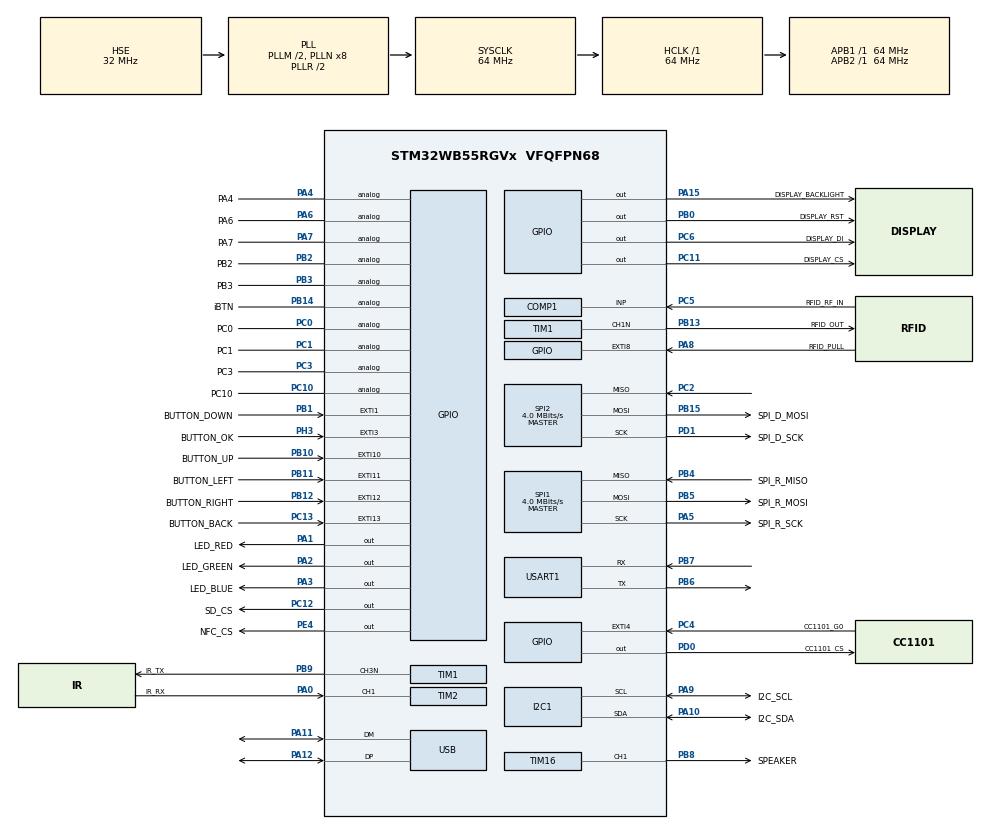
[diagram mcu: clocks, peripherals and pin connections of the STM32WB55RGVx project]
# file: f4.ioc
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PA11.GPIO_Speed=GPIO_SPEED_FREQ_VERY_HIGH
SPI1.VirtualType=VM_MASTER
PB10.GPIO_PuPd=GPIO_PULLUP
RF1.Signal=RF_RF1
SPI2.VirtualType=VM_MASTER
VP_ADC1_TempSens_Input.Mode=IN-TempSens
PC12.Signal=GPIO_Output
PB14.GPIO_Label=iBTN
PC6.GPIO_Label=DISPLAY_DI
VP_RTC_VS_RTC_Activate.Mode=RTC_Enabled
PA6.GPIO_Label=PA6
COMP1.Hysteresis=COMP_HYSTERESIS_HIGH
PA3.GPIO_Speed=GPIO_SPEED_FREQ_LOW
PB13.Signal=TIM1_CH1N
PC15-OSC32_OUT.GPIO_Label=QUARTZ_32MHZ_OUT
RCC.SYSCLKSource=RCC_SYSCLKSOURCE_PLLCLK
FREERTOS.configENABLE_FPU=1
NVIC.EXTI1_IRQn=true\:5\:0\:true\:false\:true\:false\:true\:true
NVIC.ADC1_IRQn=true\:5\:0\:true\:false\:true\:false\:true\:true
SPI1.Direction=SPI_DIRECTION_2LINES
RCC.APB2TimFreq_Value=64000000
COMP1.Mode=COMP_POWERMODE_MEDIUMSPEED
PB6.Signal=USART1_TX
PB6.Mode=Asynchronous
NVIC.TAMP_STAMP_LSECSS_IRQn=true\:5\:0\:false\:false\:true\:true\:true\:true
SPI1.CalculateBaudRate=4.0 MBits/s
PC3.Signal=GPIO_Analog
PD0.Signal=GPIO_Output
RCC.PREFETCH_ENABLE=1
NVIC.EXTI15_10_IRQn=true\:5\:0\:true\:false\:true\:false\:true\:true
PB2.Signal=GPIO_Analog
RCC.RTCClockSelection=RCC_RTCCLKSOURCE_LSE
PD1.GPIO_Label=SPI_D_SCK
PB12.GPIO_Label=BUTTON_RIGHT
LPTIM1.ClockPrescaler=LPTIM_PRESCALER_DIV32
VP_ADC1_Vref_Input.Mode=IN-Vrefint
PC4.GPIO_Label=CC1101_G0
FREERTOS.HEAP_NUMBER=4
RCC.LSE_Drive_Capability=RCC_LSEDRIVE_MEDIUMLOW
PB1.GPIO_Label=BUTTON_DOWN
NVIC.TIM2_IRQn=true\:5\:0\:true\:false\:true\:false\:true\:true
SPI1.DataSize=SPI_DATASIZE_8BIT
PE4.GPIO_Label=NFC_CS
SPI2.CalculateBaudRate=4.0 MBits/s
PA8.Signal=GPXTI8
VP_TIM1_VS_ClockSourceINT.Mode=Internal
ADC1.SamplingTime-0\#ChannelRegularConversion=ADC_SAMPLETIME_2CYCLES_5
TIM16.Pulse=145
PA0.Signal=S_TIM2_CH1
PH3-BOOT0.Signal=GPXTI3
NVIC.HSEM_IRQn=true\:5\:0\:true\:false\:true\:false\:false\:true
PB9.Signal=TIM1_CH3N
Mcu.Package=VFQFPN68
TIM2.Prescaler=64-1
PB1.Signal=GPXTI1
NVIC.TimeBase=TIM1_TRG_COM_TIM17_IRQn
SPI2.Mode=SPI_MODE_MASTER
PA2.GPIO_ModeDefaultOutputPP=GPIO_MODE_OUTPUT_OD
VP_PKA_VS_PKA.Mode=PKA_Activate
NVIC.TimeBaseIP=TIM17
PA10.Signal=I2C1_SDA
VP_RTC_VS_RTC_Calendar.Mode=RTC_Calendar
PA1.PinState=GPIO_PIN_SET
NVIC.USB_LP_IRQn=true\:5\:0\:true\:false\:true\:false\:false\:true
VP_HSEM_VS_HSEM.Mode=HSEM_Activate
RCC.APB1TimFreq_Value=64000000
FREERTOS.configGENERATE_RUN_TIME_STATS=1
PB13.Mode=Output Compare1 CH1N
TIM16.Prescaler=500 - 1
I2C1.CustomTiming=Disabled
RCC.SMPSDivider=4
PA4.GPIO_Label=PA4
NVIC.RCC_IRQn=true\:5\:0\:false\:false\:true\:true\:true\:false
RCC.HSI48_VALUE=48000000
PA5.Mode=Full_Duplex_Master
PC4.GPIO_ModeDefaultEXTI=GPIO_MODE_IT_RISING_FALLING
PA3.GPIO_ModeDefaultOutputPP=GPIO_MODE_OUTPUT_OD
FREERTOS.Tasks01=app_main,24,1024,app,As weak,NULL,Dynamic,NULL,NULL
ADC1.Rank-0\#ChannelRegularConversion=1
VP_SYS_VS_tim17.Mode=TIM17
ADC1.OffsetNumber-0\#ChannelRegularConversion=ADC_OFFSET_NONE
PA9.GPIO_Label=I2C_SCL
PC13.Signal=GPXTI13
FREERTOS.configCHECK_FOR_STACK_OVERFLOW=1
PC2.Signal=SPI2_MISO
PC6.Signal=GPIO_Output
PB11.GPIO_Label=BUTTON_LEFT
PD1.Signal=SPI2_SCK
SH.S_TIM16_CH1.0=TIM16_CH1,PWM Generation1 CH1
VP_TIM16_VS_ClockSourceINT.Mode=Enable_Timer
SPI1.CLKPhase=SPI_PHASE_2EDGE
PC0.Signal=GPIO_Analog
PC14-OSC32_IN.Signal=RCC_OSC32_IN
PD0.GPIO_Speed=GPIO_SPEED_FREQ_VERY_HIGH
PB8.GPIO_Label=SPEAKER
PA8.GPIO_Label=RFID_PULL
PC12.PinState=GPIO_PIN_SET
USB_DEVICE.PRODUCT_STRING_CDC_FS=Flipper Control Virtual ComPort
PA9.Signal=I2C1_SCL
I2C1.Timing=0x10707DBC
OSC_IN.Signal=RCC_OSC_IN
PB10.Signal=GPXTI10
PB14.Signal=GPIO_Analog
PA5.Signal=SPI1_SCK
PD1.Mode=Full_Duplex_Master
NVIC.LPTIM1_IRQn=true\:5\:0\:true\:false\:true\:false\:true\:true
RCC.RNGCLockSelection=RCC_RNGCLKSOURCE_CLK48
PB4.GPIO_Label=SPI_R_MISO
PB15.GPIO_Label=SPI_D_MOSI
SPI1.Mode=SPI_MODE_MASTER
NVIC.COMP_IRQn=true\:5\:0\:true\:false\:true\:false\:false\:true
PA1.GPIO_Label=LED_RED
PA13.Mode=Serial_Wire
PB10.GPIO_ModeDefaultEXTI=GPIO_MODE_IT_RISING_FALLING
PA4.Signal=GPIO_Analog
PB5.Signal=SPI1_MOSI
ADC1.master=1
PA5.GPIO_Label=SPI_R_SCK
OSC_IN.Mode=HSE-External-Oscillator
PC12.GPIO_Label=SD_CS
PA11.Signal=USB_DM
ProjectManager.HeapSize=0x400
NVIC.PriorityGroup=NVIC_PRIORITYGROUP_4
USB_DEVICE.APP_RX_DATA_SIZE=512
TIM2.AutoReloadPreload=TIM_AUTORELOAD_PRELOAD_ENABLE
PC3.GPIO_Label=PC3
PA3.PinState=GPIO_PIN_SET
PE4.PinState=GPIO_PIN_SET
SPI2.DataSize=SPI_DATASIZE_8BIT
VP_AES1_VS_AES.Mode=AES_Activate
PB12.GPIO_PuPd=GPIO_PULLUP
PB0.Signal=GPIO_Output
PC1.Signal=GPIO_Analog
Mcu.Family=STM32WB
OSC_OUT.GPIO_Label=QUARTZ_32KHZ_OUT
USB_DEVICE.CLASS_NAME_FS=CDC
RCC.CortexFreq_Value=64000000
TIM2.Channel-Input_Capture1_from_TI1=TIM_CHANNEL_1
ADC1.ContinuousConvMode=DISABLE
PC10.Signal=GPIO_Analog
PA0.GPIO_Label=IR_RX
PA2.GPIO_Speed=GPIO_SPEED_FREQ_LOW
PH3-BOOT0.GPIO_Label=BUTTON_OK
NVIC.EXTI3_IRQn=true\:5\:0\:true\:false\:true\:false\:true\:true
PD0.GPIO_Label=CC1101_CS
PC0.GPIO_Label=PC0
PA11.Mode=Device
PB0.GPIO_Label=DISPLAY_RST
FREERTOS.configTICK_RATE_HZ=1000
PB11.GPIO_PuPd=GPIO_PULLUP
PC13.GPIO_Label=BUTTON_BACK
PB13.GPIO_Label=RFID_OUT
PB11.Signal=GPXTI11
PB15.Signal=SPI2_MOSI
ProjectManager.StackSize=0x1000
VP_FREERTOS_VS_CMSIS_V2.Mode=CMSIS_V2
USB_DEVICE.MANUFACTURER_STRING=Flipper
PA15.GPIO_Label=DISPLAY_BACKLIGHT
PA12.Signal=USB_DP
TIM2.ICPolarity_CH1=TIM_INPUTCHANNELPOLARITY_FALLING
PB1.GPIO_PuPd=GPIO_PULLUP
RCC.HCLKFreq_Value=64000000
PB1.GPIO_ModeDefaultEXTI=GPIO_MODE_IT_RISING_FALLING
OSC_OUT.Mode=HSE-External-Oscillator
OSC_OUT.Signal=RCC_OSC_OUT
RCC.AHBFreq_Value=64000000
SPI2.BaudRatePrescaler=SPI_BAUDRATEPRESCALER_16
ADC1.Channel-0\#ChannelRegularConversion=ADC_CHANNEL_14
RCC.HSE_VALUE=32000000
FREERTOS.configUSE_TIMERS=1
FREERTOS.configENABLE_BACKWARD_COMPATIBILITY=0
NVIC.TIM1_TRG_COM_TIM17_IRQn=true\:0\:0\:false\:false\:true\:false\:false\:true
PA2.PinState=GPIO_PIN_SET
PB4.Mode=Full_Duplex_Master
RCC.LSE_Timout=1000
PC14-OSC32_IN.Mode=LSE-External-Oscillator
PD0.PinState=GPIO_PIN_SET
PA14.Mode=Serial_Wire
PE4.GPIO_Speed=GPIO_SPEED_FREQ_VERY_HIGH
PC11.GPIO_Label=DISPLAY_CS
PB5.Mode=Full_Duplex_Master
PA10.GPIO_Label=I2C_SDA
PC13.GPIO_PuPd=GPIO_PULLUP
PB7.Signal=USART1_RX
FREERTOS.INCLUDE_vTaskCleanUpResources=1
PE4.Signal=GPIO_Output
FREERTOS.configTOTAL_HEAP_SIZE=40960
RCC.APB3Freq_Value=16000000
PA6.Signal=GPIO_Analog
TIM2.Channel-Input_Capture2_from_TI1=TIM_CHANNEL_2
RCC.EnbaleCSS=true
PA2.GPIO_Label=LED_GREEN
PB11.GPIO_ModeDefaultEXTI=GPIO_MODE_IT_RISING_FALLING
VP_LPTIM1_VS_LPTIM_counterModeInternalClock.Mode=Counts__internal_clock_event_00
PA15.Signal=GPIO_Output
RCC.MSIOscState=DISABLED
SPI2.CLKPhase=SPI_PHASE_1EDGE
PA10.GPIO_Speed=GPIO_SPEED_FREQ_VERY_HIGH
PB5.GPIO_Label=SPI_R_MOSI
VP_AES2_VS_AES.Mode=AES_Activate
PC14-OSC32_IN.GPIO_Label=QUARTZ_32MHZ_IN
SPI2.Direction=SPI_DIRECTION_2LINES
PC5.Signal=SharedAnalog_PC5
SPI1.BaudRatePrescaler=SPI_BAUDRATEPRESCALER_16
OSC_IN.GPIO_Label=QUARTZ_32KHZ_IN
PA12.GPIO_Speed=GPIO_SPEED_FREQ_VERY_HIGH
COMP1.TriggerMode=COMP_TRIGGERMODE_IT_RISING_FALLING
PB4.Signal=SPI1_MISO
RCC.PLLSAI1N=6
PA3.Signal=GPIO_Output
PB3.GPIO_Label=PB3
RCC.PLLSourceVirtual=RCC_PLLSOURCE_HSE
PC15-OSC32_OUT.Mode=LSE-External-Oscillator
SH.S_TIM2_CH1.1=TIM2_CH1,Input_Capture2_from_TI1
SH.S_TIM2_CH1.0=TIM2_CH1,Input_Capture1_from_TI1
PB9.GPIO_Label=IR_TX
PC10.GPIO_Label=PC10
PA10.Mode=I2C
USB_DEVICE.VirtualModeFS=Cdc_FS
PC4.GPIO_PuPd=GPIO_PULLDOWN
PC11.Signal=GPIO_Output
FREERTOS.configUSE_TICKLESS_IDLE=2
PC4.Signal=GPXTI4
PC2.Mode=Full_Duplex_Master
VP_RNG_VS_RNG.Mode=RNG_Activate
TIM16.Channel=TIM_CHANNEL_1
RCC.AHB2CLKDivider=RCC_SYSCLK_DIV2
USART1.VirtualMode-Asynchronous=VM_ASYNC
PA13.Signal=SYS_JTMS-SWDIO
FREERTOS.configUSE_IDLE_HOOK=1
VP_COMP1_VS_VREFINT14.Mode=VREFINT_14
PA9.Mode=I2C
TIM1.Channel-Output\ Compare1\ CH1N=TIM_CHANNEL_1
FREERTOS.configRECORD_STACK_HIGH_ADDRESS=1
ProjectManager.TargetToolchain=Makefile
PB10.GPIO_Label=BUTTON_UP
VP_USB_DEVICE_VS_USB_DEVICE_CDC_FS.Mode=CDC_FS
PB9.Mode=PWM Generation3 CH3N
RCC.LPTIM1CLockSelection=RCC_LPTIM1CLKSOURCE_LSE
ADC1.EnableAnalogWatchDog1=false
RCC.USBFreq_Value=48000000
TIM1.Channel-PWM\ Generation3\ CH3N=TIM_CHANNEL_3
PC15-OSC32_OUT.Signal=RCC_OSC32_OUT
PA1.Signal=GPIO_Output
RCC.SMPSCLockSelectionVirtual=RCC_SMPSCLKSOURCE_HSE
board=custom
RCC.VCOOutputFreq_Value=128000000
PB15.Mode=Full_Duplex_Master
TIM16.Period=291
RCC.APB2Freq_Value=64000000
PC11.PinState=GPIO_PIN_SET
VP_TIM2_VS_ClockSourceINT.Mode=Internal
PA1.GPIO_Speed=GPIO_SPEED_FREQ_LOW
SH.SharedAnalog_PC5.0=COMP1_INP,INP
RCC.ADCFreq_Value=48000000
PC1.GPIO_Label=PC1
SH.SharedAnalog_PC5.1=ADC1_IN14,IN14-Single-Ended
PH3-BOOT0.GPIO_ModeDefaultEXTI=GPIO_MODE_IT_RISING_FALLING
Mcu.Name=STM32WB55RGVx
RCC.EnableCSSLSE=true
PA2.Signal=GPIO_Output
PB3.Signal=GPIO_Analog
RCC.SYSCLKFreq_VALUE=64000000
PA7.GPIO_Label=PA7
PA12.Mode=Device
PC13.GPIO_ModeDefaultEXTI=GPIO_MODE_IT_RISING_FALLING
PC5.GPIO_Label=RFID_RF_IN
RF1.Mode=RF1_Activate
PB7.Mode=Asynchronous
NVIC.EXTI9_5_IRQn=true\:5\:0\:true\:false\:true\:false\:true\:true
USB_DEVICE.APP_TX_DATA_SIZE=512
PA14.Signal=SYS_JTCK-SWCLK
PB2.GPIO_Label=PB2
PB12.GPIO_ModeDefaultEXTI=GPIO_MODE_IT_RISING_FALLING
RCC.HSI_VALUE=16000000
ADC1.NbrOfConversionFlag=1
RCC.PLLM=RCC_PLLM_DIV2
PA15.GPIO_PuPd=GPIO_PULLDOWN
PB8.Signal=S_TIM16_CH1
PA9.GPIO_Speed=GPIO_SPEED_FREQ_VERY_HIGH
RCC.APB1Freq_Value=64000000
RCC.RFWKPClockSelection=RCC_RFWKPCLKSOURCE_LSE
PC12.GPIO_Speed=GPIO_SPEED_FREQ_VERY_HIGH
VP_CRC_VS_CRC.Mode=CRC_Activate
USB_DEVICE.VirtualMode=Cdc
PB12.Signal=GPXTI12
PA3.GPIO_Label=LED_BLUE
PA7.Signal=GPIO_Analog
PA1.GPIO_ModeDefaultOutputPP=GPIO_MODE_OUTPUT_OD

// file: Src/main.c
/* USER CODE BEGIN Header */
/**
  ******************************************************************************
  * @file           : main.c
  * @brief          : Main program body
  ******************************************************************************
  * @attention
  *
  * <h2><center>&copy; Copyright (c) 2020 STMicroelectronics.
  * All rights reserved.</center></h2>
  *
  * This software component is licensed by ST under Ultimate Liberty license
  * SLA0044, the "License"; You may not use this file except in compliance with
  * the License. You may obtain a copy of the License at:
  *                             www.st.com/SLA0044
  *
  ******************************************************************************
  */
/* USER CODE END Header */
#include "main.h"
#include "cmsis_os.h"
#include "adc.h"
#include "aes.h"
#include "comp.h"
#include "crc.h"
#include "i2c.h"
#include "pka.h"
#include "rf.h"
#include "rng.h"
#include "rtc.h"
#include "spi.h"
#include "tim.h"
#include "usart.h"
#include "usb_device.h"
#include "gpio.h"

/* USER CODE BEGIN Includes */
#include "fatfs/fatfs.h"
#include "api-hal.h"
/* USER CODE END Includes */

void SystemClock_Config(void);
void MX_FREERTOS_Init(void);

int main(void)
{

  /* MCU Configuration--------------------------------------------------------*/

  /* Reset of all peripherals, Initializes the Flash interface and the Systick. */
  HAL_Init();

  /* Configure the system clock */
  SystemClock_Config();

  /* Initialize all configured peripherals */
  MX_GPIO_Init();
  MX_ADC1_Init();
  MX_I2C1_Init();
  MX_RTC_Init();
  MX_SPI1_Init();
  MX_SPI2_Init();
  MX_USART1_UART_Init();
  MX_USB_Device_Init();
  MX_TIM1_Init();
  MX_TIM2_Init();
  MX_TIM16_Init();
  MX_COMP1_Init();
  MX_RF_Init();
  MX_PKA_Init();
  MX_RNG_Init();
  MX_AES1_Init();
  MX_AES2_Init();
  MX_CRC_Init();
  /* USER CODE BEGIN 2 */
  MX_FATFS_Init();
  delay_us_init_DWT();
  api_hal_vcp_init();
  api_hal_spi_init();
  // Errata 2.2.9, Flash OPTVERR flag is always set after system reset
  __HAL_FLASH_CLEAR_FLAG(FLASH_FLAG_ALL_ERRORS);
  /* USER CODE END 2 */

  /* Init scheduler */
  osKernelInitialize();  /* Call init function for freertos objects (in freertos.c) */
  MX_FREERTOS_Init();
  /* Start scheduler */
  osKernelStart();

  /* We should never get here as control is now taken by the scheduler */
  /* Infinite loop */
  while (1)
  {

  }
}

void SystemClock_Config(void)
{
  RCC_OscInitTypeDef RCC_OscInitStruct = {0};
  RCC_ClkInitTypeDef RCC_ClkInitStruct = {0};
  RCC_PeriphCLKInitTypeDef PeriphClkInitStruct = {0};

  /** Configure LSE Drive Capability
  */
  HAL_PWR_EnableBkUpAccess();
  __HAL_RCC_LSEDRIVE_CONFIG(RCC_LSEDRIVE_MEDIUMLOW);
  /** Configure the main internal regulator output voltage
  */
  __HAL_PWR_VOLTAGESCALING_CONFIG(PWR_REGULATOR_VOLTAGE_SCALE1);
  /** Initializes the RCC Oscillators according to the specified parameters
  * in the RCC_OscInitTypeDef structure.
  */
  RCC_OscInitStruct.OscillatorType = RCC_OSCILLATORTYPE_HSI|RCC_OSCILLATORTYPE_HSE
                              |RCC_OSCILLATORTYPE_LSE;
  RCC_OscInitStruct.HSEState = RCC_HSE_ON;
  RCC_OscInitStruct.LSEState = RCC_LSE_ON;
  RCC_OscInitStruct.HSIState = RCC_HSI_ON;
  RCC_OscInitStruct.HSICalibrationValue = RCC_HSICALIBRATION_DEFAULT;
  RCC_OscInitStruct.PLL.PLLState = RCC_PLL_ON;
  RCC_OscInitStruct.PLL.PLLSource = RCC_PLLSOURCE_HSE;
  RCC_OscInitStruct.PLL.PLLM = RCC_PLLM_DIV2;
  RCC_OscInitStruct.PLL.PLLN = 8;
  RCC_OscInitStruct.PLL.PLLP = RCC_PLLP_DIV2;
  RCC_OscInitStruct.PLL.PLLR = RCC_PLLR_DIV2;
  RCC_OscInitStruct.PLL.PLLQ = RCC_PLLQ_DIV2;
  if (HAL_RCC_OscConfig(&RCC_OscInitStruct) != HAL_OK)
  {
    Error_Handler();
  }
  /** Configure the SYSCLKSource, HCLK, PCLK1 and PCLK2 clocks dividers
  */
  RCC_ClkInitStruct.ClockType = RCC_CLOCKTYPE_HCLK4|RCC_CLOCKTYPE_HCLK2
                              |RCC_CLOCKTYPE_HCLK|RCC_CLOCKTYPE_SYSCLK
                              |RCC_CLOCKTYPE_PCLK1|RCC_CLOCKTYPE_PCLK2;
  RCC_ClkInitStruct.SYSCLKSource = RCC_SYSCLKSOURCE_PLLCLK;
  RCC_ClkInitStruct.AHBCLKDivider = RCC_SYSCLK_DIV1;
  RCC_ClkInitStruct.APB1CLKDivider = RCC_HCLK_DIV1;
  RCC_ClkInitStruct.APB2CLKDivider = RCC_HCLK_DIV1;
  RCC_ClkInitStruct.AHBCLK2Divider = RCC_SYSCLK_DIV2;
  RCC_ClkInitStruct.AHBCLK4Divider = RCC_SYSCLK_DIV1;

  if (HAL_RCC_ClockConfig(&RCC_ClkInitStruct, FLASH_LATENCY_3) != HAL_OK)
  {
    Error_Handler();
  }
  /** Initializes the peripherals clocks
  */
  PeriphClkInitStruct.PeriphClockSelection = RCC_PERIPHCLK_SMPS|RCC_PERIPHCLK_RFWAKEUP
                              |RCC_PERIPHCLK_RTC|RCC_PERIPHCLK_USART1
                              |RCC_PERIPHCLK_I2C1|RCC_PERIPHCLK_CLK48SEL
                              |RCC_PERIPHCLK_USB|RCC_PERIPHCLK_RNG
                              |RCC_PERIPHCLK_ADC;
  PeriphClkInitStruct.PLLSAI1.PLLN = 6;
  PeriphClkInitStruct.PLLSAI1.PLLP = RCC_PLLP_DIV2;
  PeriphClkInitStruct.PLLSAI1.PLLQ = RCC_PLLQ_DIV2;
  PeriphClkInitStruct.PLLSAI1.PLLR = RCC_PLLR_DIV2;
  PeriphClkInitStruct.PLLSAI1.PLLSAI1ClockOut = RCC_PLLSAI1_USBCLK|RCC_PLLSAI1_ADCCLK;
  PeriphClkInitStruct.Usart1ClockSelection = RCC_USART1CLKSOURCE_PCLK2;
  PeriphClkInitStruct.I2c1ClockSelection = RCC_I2C1CLKSOURCE_PCLK1;
  PeriphClkInitStruct.UsbClockSelection = RCC_USBCLKSOURCE_PLLSAI1;
  PeriphClkInitStruct.RngClockSelection = RCC_RNGCLKSOURCE_CLK48;
  PeriphClkInitStruct.AdcClockSelection = RCC_ADCCLKSOURCE_PLLSAI1;
  PeriphClkInitStruct.RTCClockSelection = RCC_RTCCLKSOURCE_LSE;
  PeriphClkInitStruct.RFWakeUpClockSelection = RCC_RFWKPCLKSOURCE_LSE;
  PeriphClkInitStruct.SmpsClockSelection = RCC_SMPSCLKSOURCE_HSE;
  PeriphClkInitStruct.SmpsDivSelection = RCC_SMPSCLKDIV_RANGE1;
  if (HAL_RCCEx_PeriphCLKConfig(&PeriphClkInitStruct) != HAL_OK)
  {
    Error_Handler();
  }
  /** Enables the Clock Security System
  */
  HAL_RCC_EnableCSS();
  /** Enables the Clock Security System
  */
  HAL_RCCEx_EnableLSECSS();
}

void Error_Handler(void)
{
  /* USER CODE BEGIN Error_Handler_Debug */
  /* User can add his own implementation to report the HAL error return state */
  asm("bkpt 1");
  /* USER CODE END Error_Handler_Debug */
}

/************************ (C) COPYRIGHT STMicroelectronics *****END OF FILE****/

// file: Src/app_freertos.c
#include <cmsis_os2.h>
#include <FreeRTOS.h>
#include <task.h>
#include <main.h>

osThreadId_t systemdHandle;
const osThreadAttr_t systemd_attributes = {
    .name = "systemd",
    .priority = (osPriority_t) osPriorityNormal,
    .stack_size = 1024
};

void systemd(void *argument);

void MX_FREERTOS_Init(void); /* (MISRA C 2004 rule 8.1) */

/* Hook prototypes */
void configureTimerForRunTimeStats(void);
unsigned long getRunTimeCounterValue(void);
void vApplicationIdleHook(void);
void vApplicationStackOverflowHook(TaskHandle_t xTask, signed char *pcTaskName);

__weak void configureTimerForRunTimeStats(void) {
}

__weak unsigned long getRunTimeCounterValue(void) {
    return 0;
}

__weak void vApplicationIdleHook( void ) {
    /* vApplicationIdleHook() will only be called if configUSE_IDLE_HOOK is set
    to 1 in FreeRTOSConfig.h. It will be called on each iteration of the idle
    task. It is essential that code added to this hook function never attempts
    to block in any way (for example, call xQueueReceive() with a block time
    specified, or call vTaskDelay()). If the application makes use of the
    vTaskDelete() API function (as this demo application does) then it is also
    important that vApplicationIdleHook() is permitted to return to its calling
    function, because it is the responsibility of the idle task to clean up
    memory allocated by the kernel to any task that has since been deleted. */
}

__weak void vApplicationStackOverflowHook(TaskHandle_t xTask, signed char *pcTaskName) {
    /* Run time stack overflow checking is performed if
    configCHECK_FOR_STACK_OVERFLOW is defined to 1 or 2. This hook function is
    called if a stack overflow is detected. */
    asm("bkpt 1");
}

void MX_FREERTOS_Init(void) {
    systemdHandle = osThreadNew(systemd, NULL, &systemd_attributes);
}
